# STM8AL3LE89 register map
Vendor: STMicroelectronics; Series: STM8L/STM8AL, high/medium+ density; File version: 1.0
Automotive 8-bit ultra-low-power MCU with 64 Kbytes Flash, LIN, RTC, LCD, data EEPROM, timers, USARTs, I2C, SPIs, ADC, DAC, COMPs, AES
CPU: other r1p0, big endian, no MPU, no FPU, 4 interrupt priority bits
Registers are 8-bit, read-write, reset 0x0 unless marked. A register's access mark holds for its fields unless they carry their own. Offsets are from the block's base; lines under a group give offsets from that group; [hi:lo] are bit positions; {n}, {i} and the like mark numbered series; 'fields as' and 'values as' point back to an identical list; <NAME> marks a mode.

## Memory map
0x00004800 OPT blocks up to offset 0xD
0x00005000 PORTA size 0x5
0x00005005 PORTB size 0x5
0x0000500A PORTC size 0x5
0x0000500F PORTD size 0x5
0x00005014 PORTE size 0x5
0x00005019 PORTF size 0x5
0x0000501E PORTG size 0x5
0x00005023 PORTH size 0x5
0x00005028 PORTI size 0x5
0x00005050 FLASH size 0x5
0x00005070 DMA1 blocks up to offset 0x2B
0x0000509D SYSCFG size 0x3
0x000050A0 ITC_EXTI blocks up to offset 0xC
0x000050A6 WFE size 0x4
0x000050B0 RST size 0x2
0x000050B2 PWR size 0x2
0x000050C0 CLK size 0x11
0x000050D3 WWDG size 0x2
0x000050E0 IWDG size 0x3
0x000050F0 BEEP blocks up to offset 0x4
0x00005140 RTC blocks up to offset 0x51
0x00005200 SPI1 size 0x8
0x00005210 I2C1 size 0xF
0x00005230 USART1 size 0xB
0x00005250 TIM2 size 0x17
0x00005280 TIM3 size 0x17
0x000052B0 TIM1 size 0x24
0x000052E0 TIM4 size 0xA
0x000052FF IRTIM size 0x1
0x00005300 TIM5 size 0x17
0x00005340 ADC1 size 0x12
0x00005380 DAC blocks up to offset 0x32
0x000053C0 SPI2 size 0x8
0x000053D0 AES size 0x4
0x000053E0 USART2 size 0xB
0x000053F0 USART3 size 0xB
0x00005400 LCD blocks up to offset 0x22
0x00005431 RI size 0xF
0x00005440 COMP1_2 size 0x5
0x00007F00 CPU blocks up to offset 0x61
0x00007F70 ITC_SPR size 0x8
0x00007F80 SWIM size 0x1
0x00007F90 DM size 0xB

## Interrupts
1 Interrupt_IRQ1 (FLASH) — Interrupt_IRQ1 interrupt
2 Interrupt_IRQ2 (DM, DMA1) — Interrupt_IRQ2 interrupt
3 Interrupt_IRQ3 (DM, DMA1) — Interrupt_IRQ3 interrupt
4 Interrupt_IRQ4 (RTC) — Interrupt_IRQ4 interrupt
16 Interrupt_IRQ16 (AES, LCD) — Interrupt_IRQ16 interrupt
17 Interrupt_IRQ17 (CLK, DAC, DM, TIM1) — Interrupt_IRQ17 interrupt
18 Interrupt_IRQ18 (ADC1) — Interrupt_IRQ18 interrupt
19 Interrupt_IRQ19 (TIM2, USART2) — Interrupt_IRQ19 interrupt
20 Interrupt_IRQ20 (TIM2, USART2) — Interrupt_IRQ20 interrupt
21 Interrupt_IRQ21 (TIM3, USART3) — Interrupt_IRQ21 interrupt
22 Interrupt_IRQ22 (TIM3, USART3) — Interrupt_IRQ22 interrupt
23 Interrupt_IRQ23 (TIM1) — Interrupt_IRQ23 interrupt
24 Interrupt_IRQ24 (TIM1) — Interrupt_IRQ24 interrupt
25 Interrupt_IRQ25 (TIM4) — Interrupt_IRQ25 interrupt
26 Interrupt_IRQ26 (SPI1) — Interrupt_IRQ26 interrupt
27 Interrupt_IRQ27 (TIM5, USART1) — Interrupt_IRQ27 interrupt
28 Interrupt_IRQ28 (TIM5, USART1) — Interrupt_IRQ28 interrupt
29 Interrupt_IRQ29 (I2C1, SPI2) — Interrupt_IRQ29 interrupt

## ADC1
Base 0x00005340
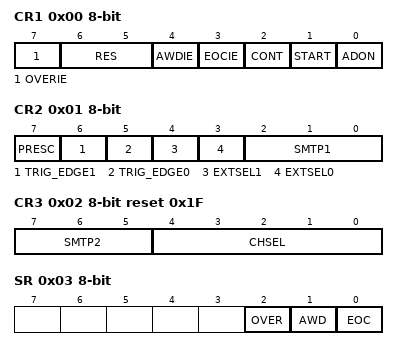
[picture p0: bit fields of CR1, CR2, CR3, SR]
0x00 CR1 — ADC1 configuration register 1
  [7] OVERIE, [6:5] RES, [4] AWDIE, [3] EOCIE, [2] CONT, [1] START, [0] ADON
0x01 CR2 — ADC1 configuration register 2
  [7] PRESC, [6] TRIG_EDGE1, [5] TRIG_EDGE0, [4] EXTSEL1, [3] EXTSEL0, [2:0] SMTP1
0x02 CR3 reset 0x1F — ADC1 configuration register 3
  [7:5] SMTP2, [4:0] CHSEL
0x03 SR — ADC1 status register
  [2] OVER, [1] AWD, [0] EOC
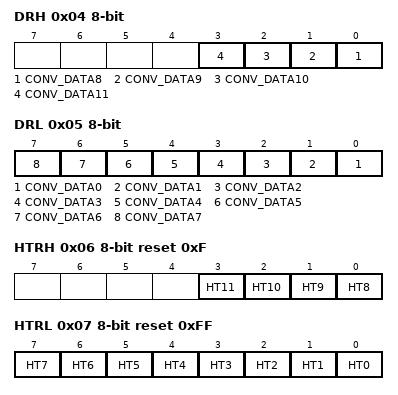
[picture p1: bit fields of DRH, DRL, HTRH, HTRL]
0x04 DRH — ADC1 data register high
  [n-8] CONV_DATA{n} (n=8..11)
0x05 DRL — ADC1 data register low
  [n] CONV_DATA{n} (n=0..7)
0x06 HTRH reset 0xF — ADC1 high threshold register high
  [n-8] HT{n} (n=8..11)
0x07 HTRL reset 0xFF — ADC1 high threshold register low
  [n] HT{n} (n=0..7)
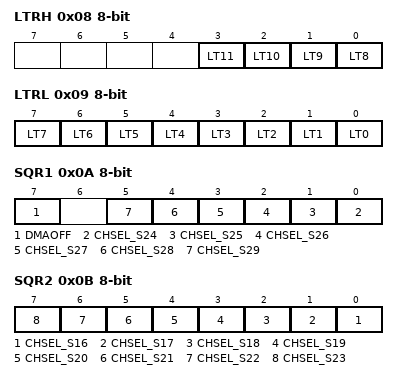
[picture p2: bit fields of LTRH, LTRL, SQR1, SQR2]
0x08 LTRH — ADC1 low threshold register high
  [n-8] LT{n} (n=8..11)
0x09 LTRL — ADC1 low threshold register low
  [n] LT{n} (n=0..7)
0x0A SQR1 — ADC1 channel sequence 1 register
  [7] DMAOFF, [n-24] CHSEL_S{n} (n=24..29)
0x0B SQR2 — ADC1 channel sequence 2 register
  [n-16] CHSEL_S{n} (n=16..23)
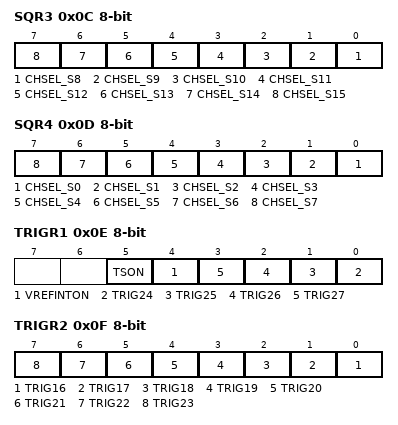
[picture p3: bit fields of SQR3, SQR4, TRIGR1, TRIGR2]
0x0C SQR3 — ADC1 channel sequence 3 register
  [n-8] CHSEL_S{n} (n=8..15)
0x0D SQR4 — ADC1 channel sequence 4 register
  [n] CHSEL_S{n} (n=0..7)
0x0E TRIGR1 — ADC1 trigger disable 1
  [5] TSON, [4] VREFINTON, [n-24] TRIG{n} (n=24..27)
0x0F TRIGR2 — ADC1 trigger disable 2
  [n-16] TRIG{n} (n=16..23)
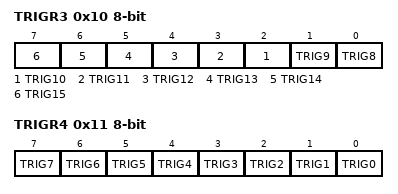
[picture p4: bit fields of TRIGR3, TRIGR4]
0x10 TRIGR3 — ADC1 trigger disable 3
  [n-8] TRIG{n} (n=8..15)
0x11 TRIGR4 — ADC1 trigger disable 4
  [n] TRIG{n} (n=0..7)
